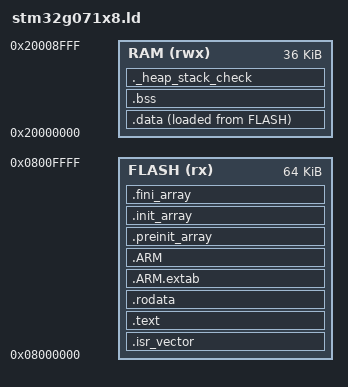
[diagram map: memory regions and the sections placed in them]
/* STM32G071C8: 64 KB flash, 36 KB RAM. Symbols as ST's startup_stm32g071xx.s
 * expects them. */

ENTRY(Reset_Handler)

MEMORY
{
    FLASH (rx)  : ORIGIN = 0x08000000, LENGTH = 64K
    RAM   (rwx) : ORIGIN = 0x20000000, LENGTH = 36K
}

_estack = ORIGIN(RAM) + LENGTH(RAM);
/* the link fails if less than these are left; the PD stack takes its state
 * from the heap once, at start-up */
_min_heap = 0x1000;
_min_stack = 0x1000;

SECTIONS
{
    .isr_vector :
    {
        . = ALIGN(4);
        KEEP(*(.isr_vector))
        . = ALIGN(4);
    } > FLASH

    .text :
    {
        . = ALIGN(4);
        *(.text)
        *(.text*)
        *(.glue_7)
        *(.glue_7t)
        *(.eh_frame)
        . = ALIGN(4);
        _etext = .;
    } > FLASH

    .rodata :
    {
        . = ALIGN(4);
        *(.rodata)
        *(.rodata*)
        . = ALIGN(4);
    } > FLASH

    .ARM.extab (READONLY) : { *(.ARM.extab* .gnu.linkonce.armextab.*) } > FLASH
    .ARM (READONLY) :
    {
        __exidx_start = .;
        *(.ARM.exidx*)
        __exidx_end = .;
    } > FLASH

    .preinit_array (READONLY) :
    {
        PROVIDE_HIDDEN(__preinit_array_start = .);
        KEEP(*(.preinit_array*))
        PROVIDE_HIDDEN(__preinit_array_end = .);
    } > FLASH
    .init_array (READONLY) :
    {
        PROVIDE_HIDDEN(__init_array_start = .);
        KEEP(*(SORT(.init_array.*)))
        KEEP(*(.init_array*))
        PROVIDE_HIDDEN(__init_array_end = .);
    } > FLASH
    .fini_array (READONLY) :
    {
        PROVIDE_HIDDEN(__fini_array_start = .);
        KEEP(*(SORT(.fini_array.*)))
        KEEP(*(.fini_array*))
        PROVIDE_HIDDEN(__fini_array_end = .);
    } > FLASH

    _sidata = LOADADDR(.data);
    .data :
    {
        . = ALIGN(4);
        _sdata = .;
        *(.data)
        *(.data*)
        . = ALIGN(4);
        _edata = .;
    } > RAM AT > FLASH

    .bss :
    {
        . = ALIGN(4);
        _sbss = .;
        __bss_start__ = _sbss;
        *(.bss)
        *(.bss*)
        *(COMMON)
        . = ALIGN(4);
        _ebss = .;
        __bss_end__ = _ebss;
    } > RAM

    ._heap_stack_check :
    {
        . = ALIGN(8);
        PROVIDE(end = .);
        PROVIDE(_end = .);
        . = . + _min_heap;
        . = . + _min_stack;
        . = ALIGN(8);
    } > RAM

    /DISCARD/ :
    {
        libc.a(*)
        libm.a(*)
        libgcc.a(*)
    }

    .ARM.attributes 0 : { *(.ARM.attributes) }
}
